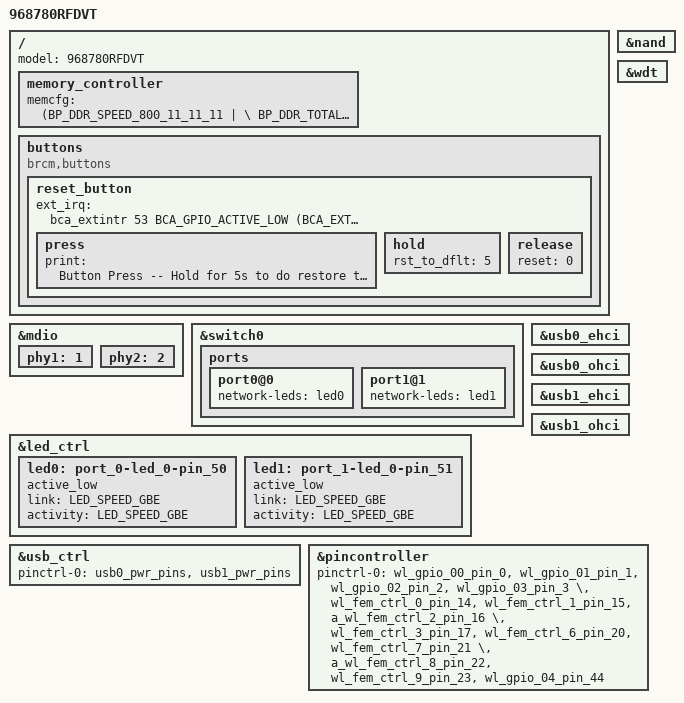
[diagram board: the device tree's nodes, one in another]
#include "inc/68780.dtsi"

/ {
    memory_controller {
        memcfg = <(BP_DDR_SPEED_800_11_11_11  | \
                   BP_DDR_TOTAL_SIZE_512MB    | \
                   BP_DDR_DEVICE_WIDTH_16     | \
                   BP_DDR_TOTAL_WIDTH_16BIT)>;
    };
};

/ {
    model = "968780RFDVT";
	 buttons {
        compatible = "brcm,buttons";
        reset_button {
            ext_irq = <&bca_extintr 53 BCA_GPIO_ACTIVE_LOW (BCA_EXTINTR_TYPE_LOW_LEVEL | BCA_EXTINTR_TYPE_SENSE_EDGE)>;
            press {
                print = "Button Press -- Hold for 5s to do restore to default";
   	 };
            hold {
                rst_to_dflt = <5>;
            };
            release {
                reset = <0>;
            };	
        };
    };
};

&mdio {
        phy1:1 {
                status = "okay";
        };

        phy2:2 {
                status = "okay";
        };
};

&switch0 {
        ports {
                port0@0 {
                        network-leds = <&led0>;
                        status = "okay";
                };

                port1@1 {
                        network-leds = <&led1>;
                        status = "okay";
                };
        };
};

&led_ctrl {
    led0: port_0-led_0-pin_50 {
              active_low;
              link = <LED_SPEED_GBE>;
              activity = <LED_SPEED_GBE>;
              status = "okay";
          };
    led1: port_1-led_0-pin_51 {
              active_low;
              link = <LED_SPEED_GBE>;
              activity = <LED_SPEED_GBE>;
              status = "okay";
          };
};

&nand {
	status = "okay";
};
&wdt {
	status = "okay";
};
&usb_ctrl {
    pinctrl-names = "default";
    pinctrl-0 = <&usb0_pwr_pins &usb1_pwr_pins>;
	status = "okay";
};
&usb0_ehci {
	status = "okay";
};
&usb0_ohci {
	status = "okay";
};
&usb1_ehci {
	status = "okay";
};
&usb1_ohci {
	status = "okay";
};

&pincontroller {
    pinctrl-names = "default";
    pinctrl-0 = <&wl_gpio_00_pin_0 &wl_gpio_01_pin_1 &wl_gpio_02_pin_2 &wl_gpio_03_pin_3 \
				&wl_fem_ctrl_0_pin_14 &wl_fem_ctrl_1_pin_15 &a_wl_fem_ctrl_2_pin_16 \
				&wl_fem_ctrl_3_pin_17 &wl_fem_ctrl_6_pin_20 &wl_fem_ctrl_7_pin_21 \
				&a_wl_fem_ctrl_8_pin_22 &wl_fem_ctrl_9_pin_23 &wl_gpio_04_pin_44 >;
};

